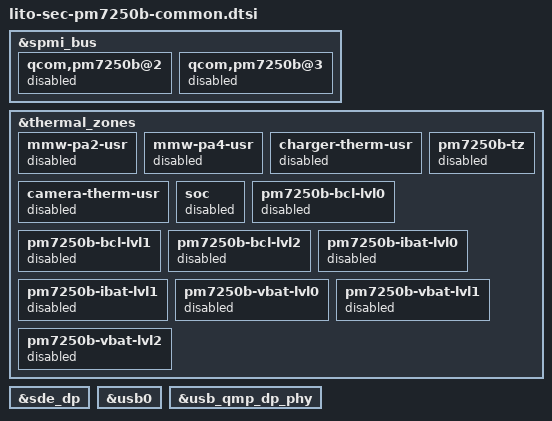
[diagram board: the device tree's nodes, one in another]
/* Copyright (c) 2019, The Linux Foundation. All rights reserved.
 *
 * This program is free software; you can redistribute it and/or modify
 * it under the terms of the GNU General Public License version 2 and
 * only version 2 as published by the Free Software Foundation.
 *
 * This program is distributed in the hope that it will be useful,
 * but WITHOUT ANY WARRANTY; without even the implied warranty of
 * MERCHANTABILITY or FITNESS FOR A PARTICULAR PURPOSE.  See the
 * GNU General Public License for more details.
 */

&spmi_bus {
	qcom,pm7250b@2 {
		status = "disabled";
	};
	qcom,pm7250b@3 {
		status = "disabled";
	};
};

&thermal_zones {
	mmw-pa2-usr {
		status = "disabled";
	};

	mmw-pa4-usr {
		status = "disabled";
	};

	charger-therm-usr {
		status = "disabled";
	};

	camera-therm-usr {
		status = "disabled";
	};

	pm7250b-tz {
		status = "disabled";
	};

	soc {
		status = "disabled";
	};

	pm7250b-bcl-lvl0 {
		status = "disabled";
	};

	pm7250b-bcl-lvl1 {
		status = "disabled";
	};

	pm7250b-bcl-lvl2 {
		status = "disabled";
	};

	pm7250b-ibat-lvl0 {
		status = "disabled";
	};

	pm7250b-ibat-lvl1 {
		status = "disabled";
	};

	pm7250b-vbat-lvl0 {
		status = "disabled";
	};

	pm7250b-vbat-lvl1 {
		status = "disabled";
	};

	pm7250b-vbat-lvl2 {
		status = "disabled";
	};
};

&sde_dp {
	/delete-property/ qcom,dp-usbpd-detection;
};

&usb0 {
	/delete-property/ extcon;
};

&usb_qmp_dp_phy {
	/delete-property/ extcon;
};
